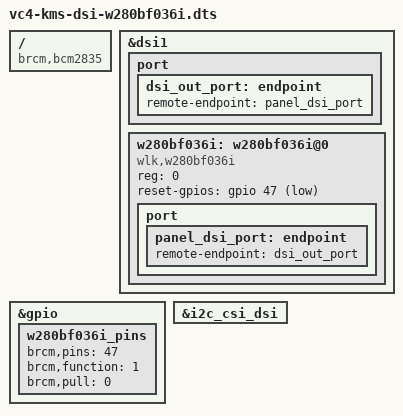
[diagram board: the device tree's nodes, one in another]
// compile: dtc -@ -I dts -O dtb -o vc4-kms-dsi-w280bf036i.dtbo vc4-kms-dsi-w280bf036i.dts

/dts-v1/;
/plugin/;

/ {
	compatible = "brcm,bcm2835";  

	fragment@0 {
		target = <&dsi1>;
		__overlay__{
			status = "okay";
			#address-cells = <1>;
			#size-cells = <0>;
			port {
				dsi_out_port:endpoint {
					remote-endpoint = <&panel_dsi_port>;
				};
			};

			w280bf036i:w280bf036i@0 {
				compatible    = "wlk,w280bf036i";
				status        = "okay";
				reg           = <0>;
				reset-gpios   = <&gpio 47 1>;   // Dummy GPIO , Unused
				port {
					panel_dsi_port: endpoint {
						remote-endpoint = <&dsi_out_port>;
					};
				};
			};
		};
	};

	fragment@1 {
		target = <&gpio>;
		__overlay__ {
			w280bf036i_pins: w280bf036i_pins {
				brcm,pins = <47>;
				brcm,function = <1>; // out
				brcm,pull = <0>; // off
			};
		};

	};
	fragment@2 {
		target = <&i2c_csi_dsi>;
		__overlay__ {
			#address-cells = <1>;
			#size-cells = <0>;
			status = "okay";
		};
	};
};

